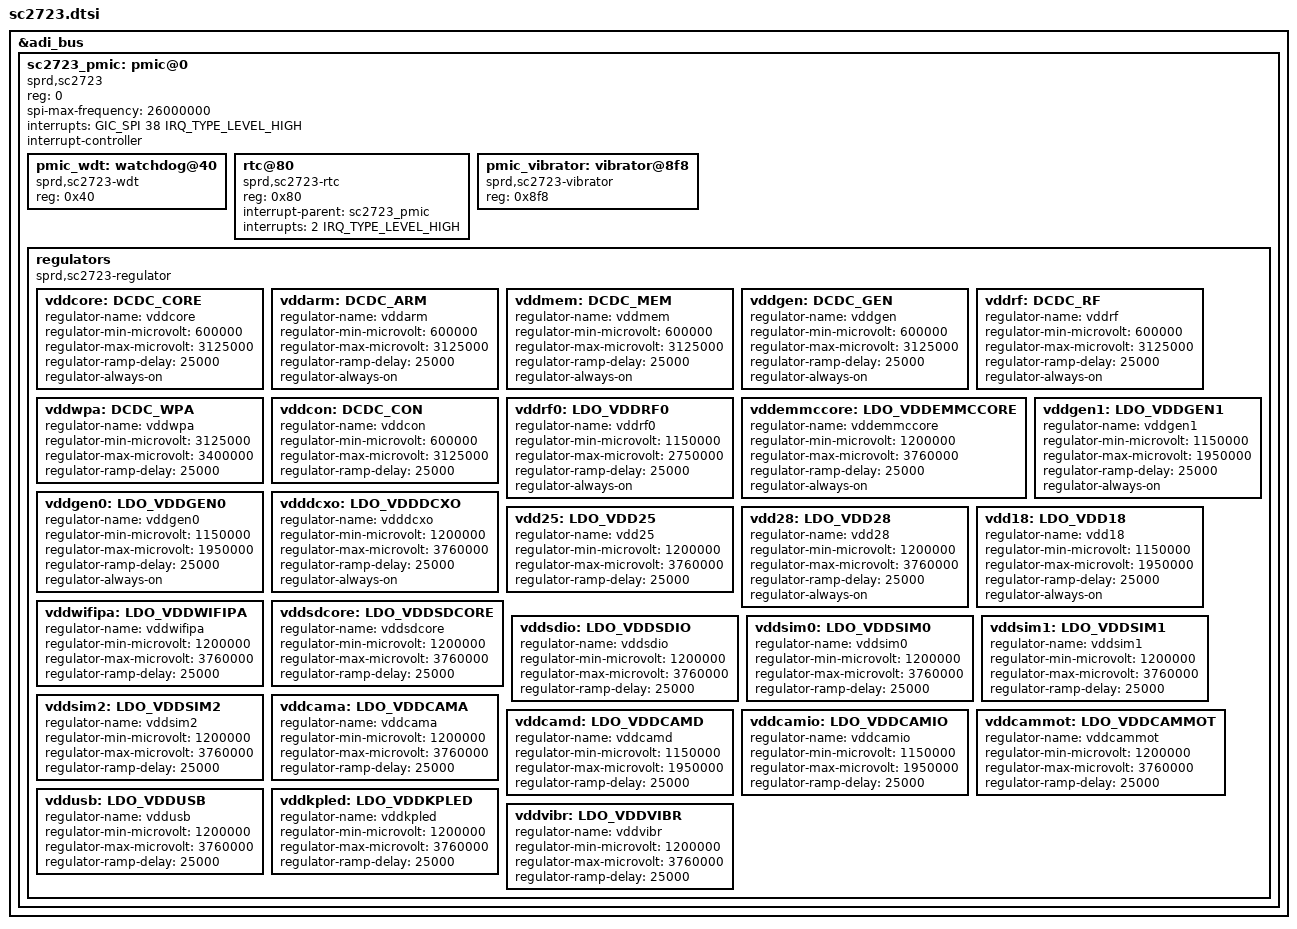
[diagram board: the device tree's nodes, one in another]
// SPDX-License-Identifier: (GPL-2.0+ OR MIT)
/*
* Spreadtrum SC2723 PMIC dts file
 *
 * Copyright (C) 2015, Spreadtrum Communications Inc.
 *
 * Copyright (C) 2025, Vladimir Panferov.
 */

&adi_bus {
	sc2723_pmic: pmic@0 {
		compatible = "sprd,sc2723";
		reg = <0>;
		spi-max-frequency = <26000000>;
		interrupts = <GIC_SPI 38 IRQ_TYPE_LEVEL_HIGH>;
		interrupt-controller;
		#interrupt-cells = <1>;
		#address-cells = <1>;
		#size-cells = <0>;

		pmic_wdt: watchdog@40 {
			compatible = "sprd,sc2723-wdt", "sprd,sc2731-wdt";
			reg = <0x40>;
		};

		rtc@80 {
			compatible = "sprd,sc2723-rtc", "sprd,sc2731-rtc";
			reg = <0x80>;
			interrupt-parent = <&sc2723_pmic>;
			interrupts = <2 IRQ_TYPE_LEVEL_HIGH>;
		};

		pmic_vibrator: vibrator@8f8 {
			compatible = "sprd,sc2723-vibrator", "sprd,sc2721-vibrator";
			reg = <0x8f8>;
		};

		regulators {
			compatible = "sprd,sc2723-regulator";

			vddcore: DCDC_CORE {
				regulator-name = "vddcore";
				regulator-min-microvolt = <600000>;
				regulator-max-microvolt = <3125000>;
				regulator-ramp-delay = <25000>;
				regulator-always-on;
			};

			vddarm: DCDC_ARM {
				regulator-name = "vddarm";
				regulator-min-microvolt = <600000>;
				regulator-max-microvolt = <3125000>;
				regulator-ramp-delay = <25000>;
				regulator-always-on;
			};

			vddmem: DCDC_MEM {
				regulator-name = "vddmem";
				regulator-min-microvolt = <600000>;
				regulator-max-microvolt = <3125000>;
				regulator-ramp-delay = <25000>;
				regulator-always-on;
			};

			vddgen: DCDC_GEN {
				regulator-name = "vddgen";
				regulator-min-microvolt = <600000>;
				regulator-max-microvolt = <3125000>;
				regulator-ramp-delay = <25000>;
				regulator-always-on;
			};

			vddrf: DCDC_RF {
				regulator-name = "vddrf";
				regulator-min-microvolt = <600000>;
				regulator-max-microvolt = <3125000>;
				regulator-ramp-delay = <25000>;
				regulator-always-on;
			};

			vddwpa: DCDC_WPA {
				regulator-name = "vddwpa";
				regulator-min-microvolt = <3125000>;
				regulator-max-microvolt = <3400000>;
				regulator-ramp-delay = <25000>;
			};

			vddcon: DCDC_CON {
				regulator-name = "vddcon";
				regulator-min-microvolt = <600000>;
				regulator-max-microvolt = <3125000>;
				regulator-ramp-delay = <25000>;
			};

			vddrf0: LDO_VDDRF0 {
				regulator-name = "vddrf0";
				regulator-min-microvolt = <1150000>;
				regulator-max-microvolt = <2750000>;
				regulator-ramp-delay = <25000>;
				regulator-always-on;
			};

			vddemmccore: LDO_VDDEMMCCORE {
				regulator-name = "vddemmccore";
				regulator-min-microvolt = <1200000>;
				regulator-max-microvolt = <3760000>;
				regulator-ramp-delay = <25000>;
				regulator-always-on;
			};

			vddgen1: LDO_VDDGEN1 {
				regulator-name = "vddgen1";
				regulator-min-microvolt = <1150000>;
				regulator-max-microvolt = <1950000>;
				regulator-ramp-delay = <25000>;
				regulator-always-on;
			};

			vddgen0: LDO_VDDGEN0 {
				regulator-name = "vddgen0";
				regulator-min-microvolt = <1150000>;
				regulator-max-microvolt = <1950000>;
				regulator-ramp-delay = <25000>;
				regulator-always-on;
			};

			vdddcxo: LDO_VDDDCXO {
				regulator-name = "vdddcxo";
				regulator-min-microvolt = <1200000>;
				regulator-max-microvolt = <3760000>;
				regulator-ramp-delay = <25000>;
				regulator-always-on;
			};

			vdd25: LDO_VDD25 {
				regulator-name = "vdd25";
				regulator-min-microvolt = <1200000>;
				regulator-max-microvolt = <3760000>;
				regulator-ramp-delay = <25000>;
			};

			vdd28: LDO_VDD28 {
				regulator-name = "vdd28";
				regulator-min-microvolt = <1200000>;
				regulator-max-microvolt = <3760000>;
				regulator-ramp-delay = <25000>;
				regulator-always-on;
			};

			vdd18: LDO_VDD18 {
				regulator-name = "vdd18";
				regulator-min-microvolt = <1150000>;
				regulator-max-microvolt = <1950000>;
				regulator-ramp-delay = <25000>;
				regulator-always-on;
			};

			vddwifipa: LDO_VDDWIFIPA {
				regulator-name = "vddwifipa";
				regulator-min-microvolt = <1200000>;
				regulator-max-microvolt = <3760000>;
				regulator-ramp-delay = <25000>;
			};

			vddsdcore: LDO_VDDSDCORE {
				regulator-name = "vddsdcore";
				regulator-min-microvolt = <1200000>;
				regulator-max-microvolt = <3760000>;
				regulator-ramp-delay = <25000>;
			};

			vddsdio: LDO_VDDSDIO {
				regulator-name = "vddsdio";
				regulator-min-microvolt = <1200000>;
				regulator-max-microvolt = <3760000>;
				regulator-ramp-delay = <25000>;
			};

			vddsim0: LDO_VDDSIM0 {
				regulator-name = "vddsim0";
				regulator-min-microvolt = <1200000>;
				regulator-max-microvolt = <3760000>;
				regulator-ramp-delay = <25000>;
			};

			vddsim1: LDO_VDDSIM1 {
				regulator-name = "vddsim1";
				regulator-min-microvolt = <1200000>;
				regulator-max-microvolt = <3760000>;
				regulator-ramp-delay = <25000>;
			};

			vddsim2: LDO_VDDSIM2 {
				regulator-name = "vddsim2";
				regulator-min-microvolt = <1200000>;
				regulator-max-microvolt = <3760000>;
				regulator-ramp-delay = <25000>;
			};

			vddcama: LDO_VDDCAMA {
				regulator-name = "vddcama";
				regulator-min-microvolt = <1200000>;
				regulator-max-microvolt = <3760000>;
				regulator-ramp-delay = <25000>;
			};

			vddcamd: LDO_VDDCAMD {
				regulator-name = "vddcamd";
				regulator-min-microvolt = <1150000>;
				regulator-max-microvolt = <1950000>;
				regulator-ramp-delay = <25000>;
			};

			vddcamio: LDO_VDDCAMIO {
				regulator-name = "vddcamio";
				regulator-min-microvolt = <1150000>;
				regulator-max-microvolt = <1950000>;
				regulator-ramp-delay = <25000>;
			};

			vddcammot: LDO_VDDCAMMOT {
				regulator-name = "vddcammot";
				regulator-min-microvolt = <1200000>;
				regulator-max-microvolt = <3760000>;
				regulator-ramp-delay = <25000>;
			};

			vddusb: LDO_VDDUSB {
				regulator-name = "vddusb";
				regulator-min-microvolt = <1200000>;
				regulator-max-microvolt = <3760000>;
				regulator-ramp-delay = <25000>;
			};

			vddkpled: LDO_VDDKPLED {
				regulator-name = "vddkpled";
				regulator-min-microvolt = <1200000>;
				regulator-max-microvolt = <3760000>;
				regulator-ramp-delay = <25000>;
			};

			vddvibr: LDO_VDDVIBR {
				regulator-name = "vddvibr";
				regulator-min-microvolt = <1200000>;
				regulator-max-microvolt = <3760000>;
				regulator-ramp-delay = <25000>;
			};
		};
	};
};
